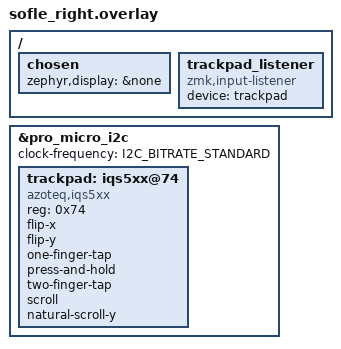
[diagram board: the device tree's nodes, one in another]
// Azoteq TPS43 trackpad configuration for right side
// Right side has NO OLED, only trackpad on I2C bus
// SDA: P0.17 (D2), SCL: P0.20 (D3)

#include <dt-bindings/i2c/i2c.h>

/ {
    // Remove OLED from chosen on right side (it's only on left)
    chosen {
        zephyr,display = &none;
    };

    // Input listener for trackpad (pattern from Research.md)
    trackpad_listener: trackpad_listener {
        compatible = "zmk,input-listener";
        device = <&trackpad>;
    };
};

&pro_micro_i2c {
    status = "okay";
    clock-frequency = <I2C_BITRATE_STANDARD>;  // Use 100kHz for stability

    trackpad: iqs5xx@74 {
        compatible = "azoteq,iqs5xx";
        reg = <0x74>;  // TPS43 standard I2C address
        status = "okay";

        // Polling mode - no GPIO pins needed
        // Successfully implemented polling mode for hardware without RDY pin

        // Flip axes for natural cursor movement
        flip-x;
        flip-y;

        // Gesture features
        one-finger-tap;      // Quick tap for left-click
        press-and-hold;      // Press and hold for click-and-drag
        two-finger-tap;      // Two-finger tap for right-click
        scroll;              // Two-finger scroll
        natural-scroll-y;    // Natural vertical scroll (content tracks finger)
    };
};
